# CORTEXA9_PRM register map
Vendor: Texas Instruments
Peripheral module from a debugger description file (folder omap4460).
Registers are 32-bit, access not given, reset values left out (the file's numbers can be read two ways) unless marked. A register's access mark holds for its fields unless they carry their own. Offsets are as the file gives them; lines under a group give offsets from that group; [hi:lo] are bit positions; {n}, {i} and the like mark numbered series; 'fields as' and 'values as' point back to an identical list; <NAME> marks a mode.

## CORTEXA9_PRM
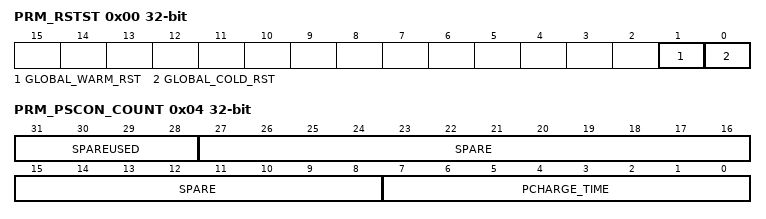
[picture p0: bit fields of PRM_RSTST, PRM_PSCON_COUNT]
0x00 PRM_RSTST — This register logs the global reset sources, thus contains information regarding the cold/warm reset events generated by global PRCM. Each bit is set upon release of the domain reset signal. Must be cleared by software.
  [1] GLOBAL_WARM_RST — Global warm reset event generated by Global PRCM (access RW W1toClr)
    0=No global warm reset; 1=Global external warm reset has occurred
  [0] GLOBAL_COLD_RST — Power-on (cold) reset event generated by global PRCM (access RW W1toClr)
    0=No power-on reset; 1=Power-on reset has occurred
0x04 PRM_PSCON_COUNT access per field — Programmable Precharge count for L1Cache. This register is useful to ensure the correct delay between toggles of pscon lines and therefore to avoid Any problem of power switch transitions. The register corresponds to the number of device system clock cycles for the SRAM precharge duration. It means that the local PRCM module waits for PCHARGE_TIME cycles of system clock. The pscon modules belongs to the local PRCM modules and are used to control the power of the CPUx.
  [31:28] SPAREUSED ro — 4 bits consumed for Last Power State Entered
  [27:8] SPARE rw — Spare programmable bits
  [7:0] PCHARGE_TIME rw — Programmable Precharge count during retention
